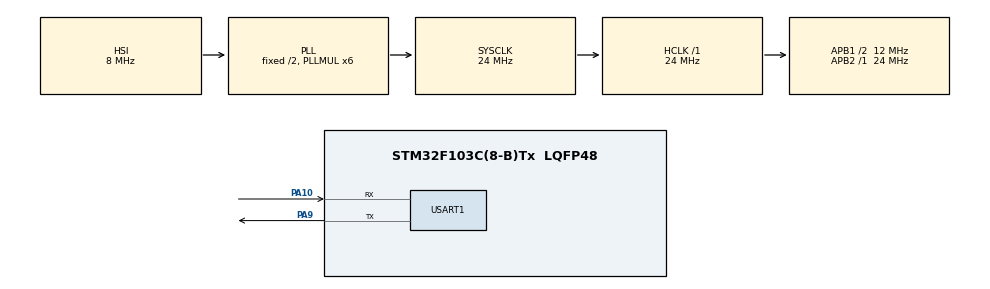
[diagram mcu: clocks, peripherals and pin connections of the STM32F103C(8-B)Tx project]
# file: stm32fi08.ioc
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Mcu.Family=STM32F1
Mcu.Name=STM32F103C(8-B)Tx
Mcu.Package=LQFP48
NVIC.PriorityGroup=NVIC_PRIORITYGROUP_4
NVIC.USART1_IRQn=true\:0\:0\:false\:false\:true\:true\:true
PA10.Mode=Asynchronous
PA10.Signal=USART1_RX
PA9.Mode=Asynchronous
PA9.Signal=USART1_TX
ProjectManager.HeapSize=0x200
ProjectManager.StackSize=0x400
ProjectManager.TargetToolchain=MDK-ARM V5
RCC.AHBFreq_Value=24000000
RCC.APB1CLKDivider=RCC_HCLK_DIV2
RCC.APB1Freq_Value=12000000
RCC.APB1TimFreq_Value=24000000
RCC.APB2Freq_Value=24000000
RCC.APB2TimFreq_Value=24000000
RCC.HCLKFreq_Value=24000000
RCC.PLLMUL=RCC_PLL_MUL6
RCC.SYSCLKFreq_VALUE=24000000
RCC.SYSCLKSource=RCC_SYSCLKSOURCE_PLLCLK
RCC.USBFreq_Value=24000000
USART1.VirtualMode=VM_ASYNC
VP_SYS_VS_ND.Mode=No_Debug
board=custom

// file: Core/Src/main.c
/* USER CODE BEGIN Header */
/**
  ******************************************************************************
  * @file           : main.c
  * @brief          : Main program body
  ******************************************************************************
  * @attention
  *
  * <h2><center>&copy; Copyright (c) 2020 STMicroelectronics.
  * All rights reserved.</center></h2>
  *
  * This software component is licensed by ST under BSD 3-Clause license,
  * the "License"; You may not use this file except in compliance with the
  * License. You may obtain a copy of the License at:
  *                        opensource.org/licenses/BSD-3-Clause
  *
  ******************************************************************************
  */
/* USER CODE END Header */
#include "main.h"
#include "usart.h"
#include "gpio.h"
#include "oled.h"
//#include "bmp.h"
#include "dhtll.h"
#include "rtc.h"
#include <string.h>
#include <stdio.h>
#include <stdlib.h>

#define LEDON HAL_GPIO_WritePin(GPIOB,GPIO_PIN_11,GPIO_PIN_SET)
#define LEDOFF HAL_GPIO_WritePin(GPIOB,GPIO_PIN_11,GPIO_PIN_RESET)

extern volatile u8 wifi_100ms_flag;
int32_t rt;
uint8_t buf[5];//温湿度缓冲区
u8 senddata[20];//串口发送缓冲区
u8 huo = 11;//火灾状态默认11正常
u8 mei = 11;
u8 ren = 11;
uint8_t jingbao = 0;//警报启动标志位
volatile uint8_t usart_data=0;       //串口
uint8_t rxdata[20]={0};   //串口
volatile uint8  usart_datasign=0;
volatile uint8  rxok=0;
volatile u8 times[5] = {0};
volatile u8 bootconst = 0;
volatile u8 bootclass = 0;
char *strjw = NULL;
extern u8 time_buf[8];
FLASH_EraseInitTypeDef f;
uint32_t PageError = 0;
extern const u8 hahastr[10];
u8 hahaconnt = 0;
u8 jingbflag = 1;

void SystemClock_Config(void);

int main(void)
{

  /* USER CODE BEGIN 1 */
  //u8   Tx_Buf[10] = {0};
  /* USER CODE END 1 */

  /* MCU Configuration--------------------------------------------------------*/

  /* Reset of all peripherals, Initializes the Flash interface and the Systick. */
  HAL_Init();

  /* Configure the system clock */
  SystemClock_Config();

  /* Initialize all configured peripherals */
  HAL_Delay(90);

  MX_GPIO_Init();
  MX_USART1_UART_Init();//串口1初始化

  OLED_Init();//oled初始化
  OLED_Clear(); //清屏
  buzz_init();//蜂鸣器
  ir_init();//火焰
  mq2_init();//煤气
  butt_init();//按键

  /* USER CODE BEGIN 2 */
  HAL_UART_Receive_IT(&huart1,&usart_data,1);//串一中断
  //ds1302_write_time();
  showbegin();//开机动画

  /* USER CODE END 2 */

  /* Infinite loop */
  /* USER CODE BEGIN WHILE */

}

 //HAL_UART_Receive_IT(&huart1,data,10);
void SystemClock_Config(void)
{
  RCC_OscInitTypeDef RCC_OscInitStruct = {0};
  RCC_ClkInitTypeDef RCC_ClkInitStruct = {0};

  /** Initializes the RCC Oscillators according to the specified parameters
  * in the RCC_OscInitTypeDef structure.
  */
  RCC_OscInitStruct.OscillatorType = RCC_OSCILLATORTYPE_HSI;
  RCC_OscInitStruct.HSIState = RCC_HSI_ON;
  RCC_OscInitStruct.HSICalibrationValue = RCC_HSICALIBRATION_DEFAULT;
  RCC_OscInitStruct.PLL.PLLState = RCC_PLL_ON;
  RCC_OscInitStruct.PLL.PLLSource = RCC_PLLSOURCE_HSI_DIV2;
  RCC_OscInitStruct.PLL.PLLMUL = RCC_PLL_MUL6;
  if (HAL_RCC_OscConfig(&RCC_OscInitStruct) != HAL_OK)
  {
    Error_Handler();
  }
  /** Initializes the CPU, AHB and APB buses clocks
  */
  RCC_ClkInitStruct.ClockType = RCC_CLOCKTYPE_HCLK|RCC_CLOCKTYPE_SYSCLK
                              |RCC_CLOCKTYPE_PCLK1|RCC_CLOCKTYPE_PCLK2;
  RCC_ClkInitStruct.SYSCLKSource = RCC_SYSCLKSOURCE_PLLCLK;
  RCC_ClkInitStruct.AHBCLKDivider = RCC_SYSCLK_DIV1;
  RCC_ClkInitStruct.APB1CLKDivider = RCC_HCLK_DIV2;
  RCC_ClkInitStruct.APB2CLKDivider = RCC_HCLK_DIV1;

  if (HAL_RCC_ClockConfig(&RCC_ClkInitStruct, FLASH_LATENCY_0) != HAL_OK)
  {
    Error_Handler();
  }
}

void Error_Handler(void)
{
}

/************************ (C) COPYRIGHT STMicroelectronics *****END OF FILE****/
